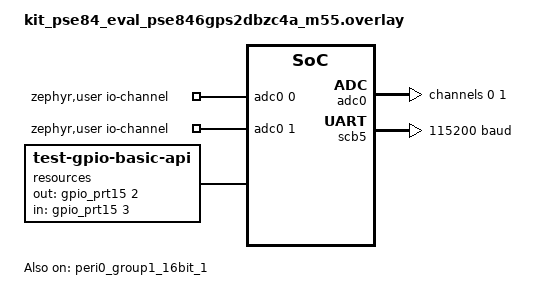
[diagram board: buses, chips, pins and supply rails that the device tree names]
/*
 * Copyright (c) 2025 Infineon Technologies AG,
 * or an affiliate of Infineon Technologies AG.
 *
 * SPDX-License-Identifier: Apache-2.0
 */

tst_dma0: &dma0 {
	status = "okay";
};

#include "kit_pse84_eval_common.overlay"

#include <zephyr/dt-bindings/adc/adc.h>

/ {
	zephyr,user {
		io-channels = <&adc0 0>, <&adc0 1>;
	};
};

&adc0 {
	status = "okay";
	#address-cells = <1>;
	#size-cells = <0>;
	channel@0 {
		reg = <0>;
		zephyr,acquisition-time = <ADC_ACQ_TIME(ADC_ACQ_TIME_MICROSECONDS, 1)>;
		zephyr,gain = "ADC_GAIN_1";
		zephyr,reference = "ADC_REF_INTERNAL";
		zephyr,resolution = <12>;
		zephyr,input-positive = <0>;
	};
	channel@1 {
		reg = <1>;
		zephyr,acquisition-time = <ADC_ACQ_TIME(ADC_ACQ_TIME_MICROSECONDS, 1)>;
		zephyr,gain = "ADC_GAIN_1";
		zephyr,reference = "ADC_REF_INTERNAL";
		zephyr,resolution = <12>;
		zephyr,input-positive = <1>;
	};
};

/ {
	resources {
		compatible = "test-gpio-basic-api";
		out-gpios = <&gpio_prt15 2 0>;
		in-gpios = <&gpio_prt15 3 0>;
	};
};

&gpio_prt15 {
	status = "okay";
};

&dma0 {
	status = "okay";
};

dut: &scb5 {
	compatible = "infineon,uart";
	status = "okay";
	current-speed = <115200>;
	clocks = <&peri0_group1_16bit_1>;
	pinctrl-0 = <&p17_1_scb5_uart_tx &p17_0_scb5_uart_rx>;
	pinctrl-names = "default";
	dmas = <&dma0 0>, <&dma0 1>;
	dma-names = "tx", "rx";
};

&p17_1_scb5_uart_tx {
	drive-push-pull;
};

&p17_0_scb5_uart_rx {
	input-enable;
};

&peri0_group1_16bit_1 {
	status = "okay";
	clock-div = <109>;
};
